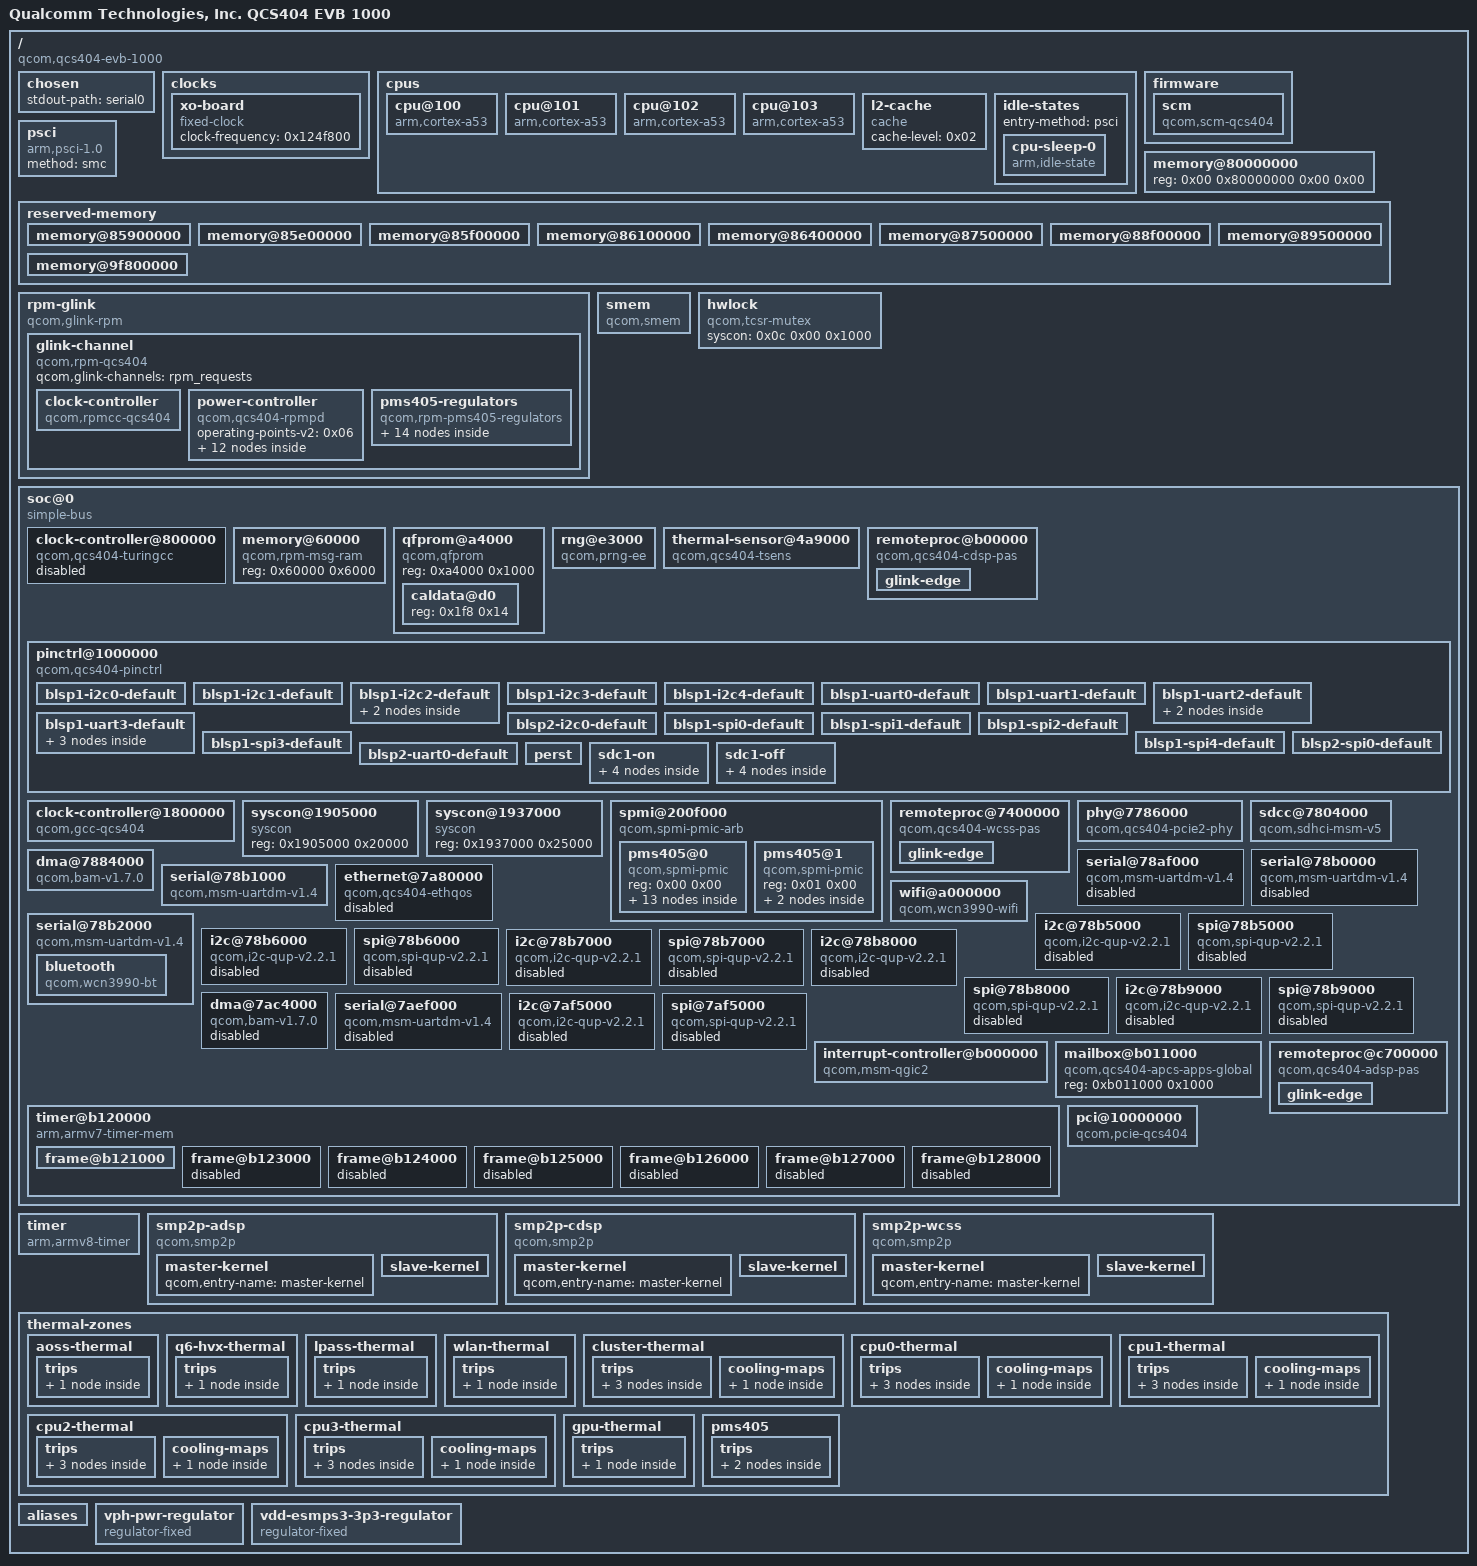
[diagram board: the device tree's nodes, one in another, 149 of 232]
/dts-v1/;

/ {
	interrupt-parent = <0x01>;
	#address-cells = <0x02>;
	#size-cells = <0x02>;
	model = "Qualcomm Technologies, Inc. QCS404 EVB 1000";
	compatible = "qcom,qcs404-evb-1000\0qcom,qcs404-evb\0qcom,qcs404";

	chosen {
		stdout-path = "serial0";
	};

	clocks {

		xo-board {
			compatible = "fixed-clock";
			#clock-cells = <0x00>;
			clock-frequency = <0x124f800>;
			phandle = <0x10>;
		};
	};

	cpus {
		#address-cells = <0x01>;
		#size-cells = <0x00>;

		cpu@100 {
			device_type = "cpu";
			compatible = "arm,cortex-a53";
			reg = <0x100>;
			enable-method = "psci";
			cpu-idle-states = <0x02>;
			next-level-cache = <0x03>;
			#cooling-cells = <0x02>;
			phandle = <0x3d>;
		};

		cpu@101 {
			device_type = "cpu";
			compatible = "arm,cortex-a53";
			reg = <0x101>;
			enable-method = "psci";
			cpu-idle-states = <0x02>;
			next-level-cache = <0x03>;
			#cooling-cells = <0x02>;
			phandle = <0x3e>;
		};

		cpu@102 {
			device_type = "cpu";
			compatible = "arm,cortex-a53";
			reg = <0x102>;
			enable-method = "psci";
			cpu-idle-states = <0x02>;
			next-level-cache = <0x03>;
			#cooling-cells = <0x02>;
			phandle = <0x3f>;
		};

		cpu@103 {
			device_type = "cpu";
			compatible = "arm,cortex-a53";
			reg = <0x103>;
			enable-method = "psci";
			cpu-idle-states = <0x02>;
			next-level-cache = <0x03>;
			#cooling-cells = <0x02>;
			phandle = <0x40>;
		};

		l2-cache {
			compatible = "cache";
			cache-level = <0x02>;
			phandle = <0x03>;
		};

		idle-states {
			entry-method = "psci";

			cpu-sleep-0 {
				compatible = "arm,idle-state";
				idle-state-name = "standalone-power-collapse";
				arm,psci-suspend-param = <0x40000003>;
				entry-latency-us = <0x7d>;
				exit-latency-us = <0xb4>;
				min-residency-us = <0x253>;
				local-timer-stop;
				phandle = <0x02>;
			};
		};
	};

	firmware {

		scm {
			compatible = "qcom,scm-qcs404\0qcom,scm";
			#reset-cells = <0x01>;
			phandle = <0x46>;
		};
	};

	memory@80000000 {
		device_type = "memory";
		reg = <0x00 0x80000000 0x00 0x00>;
	};

	psci {
		compatible = "arm,psci-1.0";
		method = "smc";
	};

	reserved-memory {
		#address-cells = <0x02>;
		#size-cells = <0x02>;
		ranges;

		memory@85900000 {
			reg = <0x00 0x85900000 0x00 0x500000>;
			no-map;
			phandle = <0x47>;
		};

		memory@85e00000 {
			reg = <0x00 0x85e00000 0x00 0x100000>;
			no-map;
			phandle = <0x48>;
		};

		memory@85f00000 {
			reg = <0x00 0x85f00000 0x00 0x200000>;
			no-map;
			phandle = <0x0a>;
		};

		memory@86100000 {
			reg = <0x00 0x86100000 0x00 0x300000>;
			no-map;
			phandle = <0x49>;
		};

		memory@86400000 {
			reg = <0x00 0x86400000 0x00 0x1100000>;
			no-map;
			phandle = <0x18>;
		};

		memory@87500000 {
			reg = <0x00 0x87500000 0x00 0x1a00000>;
			no-map;
			phandle = <0x37>;
		};

		memory@88f00000 {
			reg = <0x00 0x88f00000 0x00 0x600000>;
			no-map;
			phandle = <0x13>;
		};

		memory@89500000 {
			reg = <0x00 0x89500000 0x00 0x100000>;
			no-map;
			phandle = <0x22>;
		};

		memory@9f800000 {
			reg = <0x00 0x9f800000 0x00 0x800000>;
			no-map;
			phandle = <0x4a>;
		};
	};

	rpm-glink {
		compatible = "qcom,glink-rpm";
		interrupts = <0x00 0xa8 0x01>;
		qcom,rpm-msg-ram = <0x04>;
		mboxes = <0x05 0x00>;

		glink-channel {
			compatible = "qcom,rpm-qcs404";
			qcom,glink-channels = "rpm_requests";
			phandle = <0x4b>;

			clock-controller {
				compatible = "qcom,rpmcc-qcs404";
				#clock-cells = <0x01>;
				phandle = <0x4c>;
			};

			power-controller {
				compatible = "qcom,qcs404-rpmpd";
				#power-domain-cells = <0x01>;
				operating-points-v2 = <0x06>;
				phandle = <0x4d>;

				opp-table {
					compatible = "operating-points-v2";
					phandle = <0x06>;

					opp1 {
						opp-level = <0x10>;
						phandle = <0x4e>;
					};

					opp2 {
						opp-level = <0x20>;
						phandle = <0x4f>;
					};

					opp3 {
						opp-level = <0x30>;
						phandle = <0x50>;
					};

					opp4 {
						opp-level = <0x40>;
						phandle = <0x51>;
					};

					opp5 {
						opp-level = <0x80>;
						phandle = <0x52>;
					};

					opp6 {
						opp-level = <0xc0>;
						phandle = <0x53>;
					};

					opp7 {
						opp-level = <0x100>;
						phandle = <0x54>;
					};

					opp8 {
						opp-level = <0x140>;
						phandle = <0x55>;
					};

					opp9 {
						opp-level = <0x180>;
						phandle = <0x56>;
					};

					opp10 {
						opp-level = <0x1a0>;
						phandle = <0x57>;
					};

					opp11 {
						opp-level = <0x200>;
						phandle = <0x58>;
					};
				};
			};

			pms405-regulators {
				compatible = "qcom,rpm-pms405-regulators";
				vdd_s1-supply = <0x07>;
				vdd_s2-supply = <0x07>;
				vdd_s3-supply = <0x07>;
				vdd_s4-supply = <0x07>;
				vdd_s5-supply = <0x07>;
				vdd_l1_l2-supply = <0x08>;
				vdd_l3_l8-supply = <0x08>;
				vdd_l4-supply = <0x08>;
				vdd_l5_l6-supply = <0x09>;
				vdd_l7-supply = <0x07>;
				vdd_l9-supply = <0x08>;
				vdd_l10_l11_l12_l13-supply = <0x07>;

				s4 {
					regulator-min-microvolt = <0x1a5e00>;
					regulator-max-microvolt = <0x1d4c00>;
					phandle = <0x09>;
				};

				s5 {
					regulator-min-microvolt = <0x14a140>;
					regulator-max-microvolt = <0x14a140>;
					phandle = <0x08>;
				};

				l1 {
					regulator-min-microvolt = <0x12ebc0>;
					regulator-max-microvolt = <0x14a140>;
					phandle = <0x24>;
				};

				l2 {
					regulator-min-microvolt = <0xffdc0>;
					regulator-max-microvolt = <0x138800>;
					phandle = <0x23>;
				};

				l3 {
					regulator-min-microvolt = <0xffdc0>;
					regulator-max-microvolt = <0x11b340>;
					phandle = <0x1a>;
				};

				l4 {
					regulator-min-microvolt = <0x1174c0>;
					regulator-max-microvolt = <0x132a40>;
					phandle = <0x59>;
				};

				l5 {
					regulator-min-microvolt = <0x1b7740>;
					regulator-max-microvolt = <0x1b7740>;
					phandle = <0x1b>;
				};

				l6 {
					regulator-min-microvolt = <0x1b7740>;
					regulator-max-microvolt = <0x1b7740>;
					regulator-always-on;
					phandle = <0x26>;
				};

				l7 {
					regulator-min-microvolt = <0x18a880>;
					regulator-max-microvolt = <0x2dc6c0>;
					phandle = <0x5a>;
				};

				l8 {
					regulator-min-microvolt = <0x115580>;
					regulator-max-microvolt = <0x14a140>;
					phandle = <0x5b>;
				};

				l10 {
					regulator-min-microvolt = <0x2cccc0>;
					regulator-max-microvolt = <0x2f1e80>;
					phandle = <0x5c>;
				};

				l11 {
					regulator-min-microvolt = <0x292340>;
					regulator-max-microvolt = <0x326a40>;
					phandle = <0x5d>;
				};

				l12 {
					regulator-min-microvolt = <0x2d49c0>;
					regulator-max-microvolt = <0x325aa0>;
					phandle = <0x5e>;
				};

				l13 {
					regulator-min-microvolt = <0x2dc6c0>;
					regulator-max-microvolt = <0x325aa0>;
					phandle = <0x5f>;
				};
			};
		};
	};

	smem {
		compatible = "qcom,smem";
		memory-region = <0x0a>;
		qcom,rpm-msg-ram = <0x04>;
		hwlocks = <0x0b 0x03>;
	};

	hwlock {
		compatible = "qcom,tcsr-mutex";
		syscon = <0x0c 0x00 0x1000>;
		#hwlock-cells = <0x01>;
		phandle = <0x0b>;
	};

	soc@0 {
		#address-cells = <0x01>;
		#size-cells = <0x01>;
		ranges = <0x00 0x00 0x00 0xffffffff>;
		compatible = "simple-bus";
		phandle = <0x60>;

		clock-controller@800000 {
			compatible = "qcom,qcs404-turingcc";
			reg = <0x800000 0x30000>;
			clocks = <0x0d 0x8f>;
			#clock-cells = <0x01>;
			#reset-cells = <0x01>;
			status = "disabled";
			phandle = <0x11>;
		};

		memory@60000 {
			compatible = "qcom,rpm-msg-ram";
			reg = <0x60000 0x6000>;
			phandle = <0x04>;
		};

		qfprom@a4000 {
			compatible = "qcom,qfprom";
			reg = <0xa4000 0x1000>;
			#address-cells = <0x01>;
			#size-cells = <0x01>;
			phandle = <0x61>;

			caldata@d0 {
				reg = <0x1f8 0x14>;
				phandle = <0x0e>;
			};
		};

		rng@e3000 {
			compatible = "qcom,prng-ee";
			reg = <0xe3000 0x1000>;
			clocks = <0x0d 0x4e>;
			clock-names = "core";
			phandle = <0x62>;
		};

		thermal-sensor@4a9000 {
			compatible = "qcom,qcs404-tsens\0qcom,tsens-v1";
			reg = <0x4a9000 0x1000 0x4a8000 0x1000>;
			nvmem-cells = <0x0e>;
			nvmem-cell-names = "calib";
			#qcom,sensors = <0x0a>;
			#thermal-sensor-cells = <0x01>;
			phandle = <0x3b>;
		};

		remoteproc@b00000 {
			compatible = "qcom,qcs404-cdsp-pas";
			reg = <0xb00000 0x4040>;
			interrupts-extended = <0x01 0x00 0xe5 0x01 0x0f 0x00 0x01 0x0f 0x01 0x01 0x0f 0x02 0x01 0x0f 0x03 0x01>;
			interrupt-names = "wdog\0fatal\0ready\0handover\0stop-ack";
			clocks = <0x10 0x0d 0x8f 0x0d 0x91 0x0d 0x90 0x11 0x02 0x11 0x03 0x11 0x01 0x11 0x00>;
			clock-names = "xo\0sway\0tbu\0bimc\0ahb_aon\0q6ss_slave\0q6ss_master\0q6_axim";
			resets = <0x0d 0x0e>;
			reset-names = "restart";
			qcom,halt-regs = <0x12 0x19004>;
			memory-region = <0x13>;
			qcom,smem-states = <0x14 0x00>;
			qcom,smem-state-names = "stop";
			status = "ok";
			phandle = <0x63>;

			glink-edge {
				interrupts = <0x00 0x8d 0x01>;
				qcom,remote-pid = <0x05>;
				mboxes = <0x05 0x0c>;
				label = "cdsp";
			};
		};

		pinctrl@1000000 {
			compatible = "qcom,qcs404-pinctrl";
			reg = <0x1000000 0x200000 0x1300000 0x200000 0x7b00000 0x200000>;
			reg-names = "south\0north\0east";
			interrupts = <0x00 0xd0 0x04>;
			gpio-ranges = <0x15 0x00 0x00 0x78>;
			gpio-controller;
			#gpio-cells = <0x02>;
			interrupt-controller;
			#interrupt-cells = <0x02>;
			phandle = <0x15>;

			blsp1-i2c0-default {
				pins = "gpio32\0gpio33";
				function = "blsp_i2c0";
				phandle = <0x28>;
			};

			blsp1-i2c1-default {
				pins = "gpio24\0gpio25";
				function = "blsp_i2c1";
				phandle = <0x2a>;
			};

			blsp1-i2c2-default {
				phandle = <0x2c>;

				sda {
					pins = "gpio19";
					function = "blsp_i2c_sda_a2";
				};

				scl {
					pins = "gpio20";
					function = "blsp_i2c_scl_a2";
				};
			};

			blsp1-i2c3-default {
				pins = "gpio84\0gpio85";
				function = "blsp_i2c3";
				phandle = <0x2e>;
			};

			blsp1-i2c4-default {
				pins = "gpio117\0gpio118";
				function = "blsp_i2c4";
				phandle = <0x30>;
			};

			blsp1-uart0-default {
				pins = "gpio30\0gpio31\0gpio32\0gpio33";
				function = "blsp_uart0";
				phandle = <0x1f>;
			};

			blsp1-uart1-default {
				pins = "gpio22\0gpio23";
				function = "blsp_uart1";
				phandle = <0x20>;
			};

			blsp1-uart2-default {
				phandle = <0x21>;

				rx {
					pins = "gpio18";
					function = "blsp_uart_rx_a2";
					drive-strength = <0x02>;
					bias-disable;
				};

				tx {
					pins = "gpio17";
					function = "blsp_uart_tx_a2";
					drive-strength = <0x02>;
					bias-disable;
				};
			};

			blsp1-uart3-default {
				pins = "gpio82\0gpio83\0gpio84\0gpio85";
				function = "blsp_uart3";
				phandle = <0x25>;

				cts {
					pins = "gpio84";
					bias-disable;
				};

				rts-tx {
					pins = "gpio85\0gpio82";
					drive-strength = <0x02>;
					bias-disable;
				};

				rx {
					pins = "gpio83";
					bias-pull-up;
				};
			};

			blsp2-i2c0-default {
				pins = "gpio28\0gpio29";
				function = "blsp_i2c5";
				phandle = <0x34>;
			};

			blsp1-spi0-default {
				pins = "gpio30\0gpio31\0gpio32\0gpio33";
				function = "blsp_spi0";
				phandle = <0x29>;
			};

			blsp1-spi1-default {
				pins = "gpio22\0gpio23\0gpio24\0gpio25";
				function = "blsp_spi1";
				phandle = <0x2b>;
			};

			blsp1-spi2-default {
				pins = "gpio17\0gpio18\0gpio19\0gpio20";
				function = "blsp_spi2";
				phandle = <0x2d>;
			};

			blsp1-spi3-default {
				pins = "gpio82\0gpio83\0gpio84\0gpio85";
				function = "blsp_spi3";
				phandle = <0x2f>;
			};

			blsp1-spi4-default {
				pins = "gpio37\0gpio38\0gpio117\0gpio118";
				function = "blsp_spi4";
				phandle = <0x31>;
			};

			blsp2-spi0-default {
				pins = "gpio26\0gpio27\0gpio28\0gpio29";
				function = "blsp_spi5";
				phandle = <0x35>;
			};

			blsp2-uart0-default {
				pins = "gpio26\0gpio27\0gpio28\0gpio29";
				function = "blsp_uart5";
				phandle = <0x33>;
			};

			perst {
				pins = "gpio43";
				function = "gpio";
				drive-strength = <0x02>;
				bias-disable;
				output-low;
				phandle = <0x3a>;
			};

			sdc1-on {
				phandle = <0x1c>;

				clk {
					pins = "sdc1_clk";
					bias-disable;
					drive-strength = <0x10>;
				};

				cmd {
					pins = "sdc1_cmd";
					bias-pull-up;
					drive-strength = <0x0a>;
				};

				data {
					pins = "sdc1_data";
					bias-pull-up;
					drive-strength = <0x0a>;
				};

				rclk {
					pins = "sdc1_rclk";
					bias-pull-down;
				};
			};

			sdc1-off {
				phandle = <0x1d>;

				clk {
					pins = "sdc1_clk";
					bias-disable;
					drive-strength = <0x02>;
				};

				cmd {
					pins = "sdc1_cmd";
					bias-pull-up;
					drive-strength = <0x02>;
				};

				data {
					pins = "sdc1_data";
					bias-pull-up;
					drive-strength = <0x02>;
				};

				rclk {
					pins = "sdc1_rclk";
					bias-pull-down;
				};
			};
		};

		clock-controller@1800000 {
			compatible = "qcom,gcc-qcs404";
			reg = <0x1800000 0x80000>;
			#clock-cells = <0x01>;
			#reset-cells = <0x01>;
			assigned-clocks = <0x0d 0x00>;
			assigned-clock-rates = <0x124f800>;
			protected-clocks = <0x90 0x8f 0x92 0x91 0x8d 0x8e>;
			phandle = <0x0d>;
		};

		syscon@1905000 {
			compatible = "syscon";
			reg = <0x1905000 0x20000>;
			phandle = <0x0c>;
		};

		syscon@1937000 {
			compatible = "syscon";
			reg = <0x1937000 0x25000>;
			phandle = <0x12>;
		};

		spmi@200f000 {
			compatible = "qcom,spmi-pmic-arb";
			reg = <0x200f000 0x1000 0x2400000 0x800000 0x2c00000 0x800000 0x3800000 0x200000 0x200a000 0x2100>;
			reg-names = "core\0chnls\0obsrvr\0intr\0cnfg";
			interrupt-names = "periph_irq";
			interrupts = <0x00 0xbe 0x04>;
			qcom,ee = <0x00>;
			qcom,channel = <0x00>;
			#address-cells = <0x02>;
			#size-cells = <0x00>;
			interrupt-controller;
			#interrupt-cells = <0x04>;
			phandle = <0x64>;

			pms405@0 {
				compatible = "qcom,spmi-pmic";
				reg = <0x00 0x00>;
				#address-cells = <0x01>;
				#size-cells = <0x00>;
				phandle = <0x65>;

				gpio@c000 {
					compatible = "qcom,pms405-gpio";
					reg = <0xc000>;
					gpio-controller;
					#gpio-cells = <0x02>;
					interrupts = <0x00 0xc0 0x00 0x00 0x00 0xc1 0x00 0x00 0x00 0xc2 0x00 0x00 0x00 0xc3 0x00 0x00 0x00 0xc4 0x00 0x00 0x00 0xc5 0x00 0x00 0x00 0xc6 0x00 0x00 0x00 0xc7 0x00 0x00 0x00 0xc8 0x00 0x00 0x00 0xc9 0x00 0x00 0x00 0xca 0x00 0x00 0x00 0xcb 0x00 0x00>;
					phandle = <0x66>;
				};

				pon@800 {
					compatible = "qcom,pms405-pon";
					reg = <0x800>;
					mode-bootloader = <0x02>;
					mode-recovery = <0x01>;

					pwrkey {
						compatible = "qcom,pm8941-pwrkey";
						interrupts = <0x00 0x08 0x00 0x03>;
						debounce = <0x3d09>;
						bias-pull-up;
						linux,code = <0x74>;
					};
				};

				temp-alarm@2400 {
					compatible = "qcom,spmi-temp-alarm";
					reg = <0x2400>;
					interrupts = <0x00 0x24 0x00 0x01>;
					io-channels = <0x16 0x06>;
					io-channel-names = "thermal";
					#thermal-sensor-cells = <0x00>;
					phandle = <0x45>;
				};

				adc@3100 {
					compatible = "qcom,pms405-adc\0qcom,spmi-adc-rev2";
					reg = <0x3100>;
					interrupts = <0x00 0x31 0x00 0x01>;
					#address-cells = <0x01>;
					#size-cells = <0x00>;
					#io-channel-cells = <0x01>;
					phandle = <0x16>;

					ref_gnd@0 {
						reg = <0x00>;
						qcom,pre-scaling = <0x01 0x01>;
					};

					vref_1p25@1 {
						reg = <0x01>;
						qcom,pre-scaling = <0x01 0x01>;
					};

					vph_pwr@131 {
						reg = <0x83>;
						qcom,pre-scaling = <0x01 0x03>;
						phandle = <0x67>;
					};

					die_temp@6 {
						reg = <0x06>;
						qcom,pre-scaling = <0x01 0x01>;
					};

					thermistor1@77 {
						reg = <0x4d>;
						qcom,ratiometric;
						qcom,hw-settle-time = <0xc8>;
						qcom,pre-scaling = <0x01 0x01>;
						phandle = <0x68>;
					};

					thermistor3@79 {
						reg = <0x4f>;
						qcom,ratiometric;
						qcom,hw-settle-time = <0xc8>;
						qcom,pre-scaling = <0x01 0x01>;
						phandle = <0x69>;
					};

					xo_temp@76 {
						reg = <0x4c>;
						qcom,ratiometric;
						qcom,hw-settle-time = <0xc8>;
						qcom,pre-scaling = <0x01 0x01>;
						phandle = <0x6a>;
					};
				};

				rtc@6000 {
					compatible = "qcom,pm8941-rtc";
					reg = <0x6000>;
					reg-names = "rtc\0alarm";
					interrupts = <0x00 0x61 0x01 0x00>;
				};
			};

			pms405@1 {
				compatible = "qcom,spmi-pmic";
				reg = <0x01 0x00>;
				phandle = <0x6b>;

				regulators {
					compatible = "qcom,pms405-regulators";
					vdd_s3-supply = <0x07>;
					phandle = <0x6c>;

					s3 {
						regulator-always-on;
						regulator-boot-on;
						regulator-name = "vdd_apc";
						regulator-initial-mode = <0x01>;
						regulator-min-microvolt = <0xffdc0>;
						regulator-max-microvolt = <0x151e40>;
						phandle = <0x6d>;
					};
				};
			};
		};

		remoteproc@7400000 {
			compatible = "qcom,qcs404-wcss-pas";
			reg = <0x7400000 0x4040>;
			interrupts-extended = <0x01 0x00 0x99 0x01 0x17 0x00 0x01 0x17 0x01 0x01 0x17 0x02 0x01 0x17 0x03 0x01>;
			interrupt-names = "wdog\0fatal\0ready\0handover\0stop-ack";
			clocks = <0x10>;
			clock-names = "xo";
			memory-region = <0x18>;
			qcom,smem-states = <0x19 0x00>;
			qcom,smem-state-names = "stop";
			status = "ok";
			phandle = <0x6e>;

			glink-edge {
				interrupts = <0x00 0x9c 0x01>;
				qcom,remote-pid = <0x01>;
				mboxes = <0x05 0x10>;
				label = "wcss";
			};
		};

		phy@7786000 {
			compatible = "qcom,qcs404-pcie2-phy\0qcom,pcie2-phy";
			reg = <0x7786000 0xb8>;
			clocks = <0x0d 0x47>;
			resets = <0x0d 0x0c 0x0d 0x15>;
			reset-names = "phy\0pipe";
			clock-output-names = "pcie_0_pipe_clk";
			#phy-cells = <0x00>;
			status = "ok";
			vdda-vp-supply = <0x1a>;
			vdda-vph-supply = <0x1b>;
			phandle = <0x39>;
		};

		sdcc@7804000 {
			compatible = "qcom,sdhci-msm-v5";
			reg = <0x7804000 0x1000 0x7805000 0x1000>;
			reg-names = "hc_mem\0cmdq_mem";
			interrupts = <0x00 0x7b 0x04 0x00 0x8a 0x04>;
			interrupt-names = "hc_irq\0pwr_irq";
			clocks = <0x0d 0x53 0x0d 0x52 0x10>;
			clock-names = "core\0iface\0xo";
			status = "ok";
			mmc-ddr-1_8v;
			mmc-hs400-1_8v;
			bus-width = <0x08>;
			non-removable;
			pinctrl-names = "default\0sleep";
			pinctrl-0 = <0x1c>;
			pinctrl-1 = <0x1d>;
			phandle = <0x6f>;
		};

		dma@7884000 {
			compatible = "qcom,bam-v1.7.0";
			reg = <0x7884000 0x25000>;
			interrupts = <0x00 0xee 0x04>;
			clocks = <0x0d 0x1b>;
			clock-names = "bam_clk";
			#dma-cells = <0x01>;
			qcom,ee = <0x00>;
			status = "okay";
			qcom,controlled-remotely;
			phandle = <0x1e>;
		};

		serial@78af000 {
			compatible = "qcom,msm-uartdm-v1.4\0qcom,msm-uartdm";
			reg = <0x78af000 0x200>;
			interrupts = <0x00 0x6b 0x04>;
			clocks = <0x0d 0x26 0x0d 0x1b>;
			clock-names = "core\0iface";
			dmas = <0x1e 0x01 0x1e 0x00>;
			dma-names = "rx\0tx";
			pinctrl-names = "default";
			pinctrl-0 = <0x1f>;
			status = "disabled";
			phandle = <0x70>;
		};

		serial@78b0000 {
			compatible = "qcom,msm-uartdm-v1.4\0qcom,msm-uartdm";
			reg = <0x78b0000 0x200>;
			interrupts = <0x00 0x6c 0x04>;
			clocks = <0x0d 0x27 0x0d 0x1b>;
			clock-names = "core\0iface";
			dmas = <0x1e 0x03 0x1e 0x02>;
			dma-names = "rx\0tx";
			pinctrl-names = "default";
			pinctrl-0 = <0x20>;
			status = "disabled";
			phandle = <0x71>;
		};

		serial@78b1000 {
			compatible = "qcom,msm-uartdm-v1.4\0qcom,msm-uartdm";
			reg = <0x78b1000 0x200>;
			interrupts = <0x00 0x76 0x04>;
			clocks = <0x0d 0x28 0x0d 0x1b>;
			clock-names = "core\0iface";
			dmas = <0x1e 0x05 0x1e 0x04>;
			dma-names = "rx\0tx";
			pinctrl-names = "default";
			pinctrl-0 = <0x21>;
			status = "okay";
			phandle = <0x72>;
		};

		ethernet@7a80000 {
			compatible = "qcom,qcs404-ethqos";
			reg = <0x7a80000 0x10000 0x7a96000 0x100>;
			reg-names = "stmmaceth\0rgmii";
			clock-names = "stmmaceth\0pclk\0ptp_ref\0rgmii";
			clocks = <0x0d 0x31 0x0d 0x34 0x0d 0x32 0x0d 0x33>;
			interrupts = <0x00 0x38 0x04 0x00 0x37 0x04>;
			interrupt-names = "macirq\0eth_lpi";
			snps,tso;
			rx-fifo-depth = <0x1000>;
			tx-fifo-depth = <0x1000>;
			status = "disabled";
			phandle = <0x73>;
		};

		wifi@a000000 {
			compatible = "qcom,wcn3990-wifi";
			reg = <0xa000000 0x800000>;
			reg-names = "membase";
			memory-region = <0x22>;
			interrupts = <0x00 0x115 0x04 0x00 0x116 0x04 0x00 0x117 0x04 0x00 0x118 0x04 0x00 0x119 0x04 0x00 0x11a 0x04 0x00 0x11b 0x04 0x00 0x11c 0x04 0x00 0x11d 0x04 0x00 0x11e 0x04 0x00 0x11f 0x04 0x00 0x120 0x04>;
			status = "okay";
			vdd-0.8-cx-mx-supply = <0x23>;
			vdd-1.8-xo-supply = <0x1b>;
			vdd-1.3-rfa-supply = <0x24>;
			phandle = <0x74>;
		};

		serial@78b2000 {
			compatible = "qcom,msm-uartdm-v1.4\0qcom,msm-uartdm";
			reg = <0x78b2000 0x200>;
			interrupts = <0x00 0x77 0x04>;
			clocks = <0x0d 0x29 0x0d 0x1b>;
			clock-names = "core\0iface";
			dmas = <0x1e 0x07 0x1e 0x06>;
			dma-names = "rx\0tx";
			pinctrl-names = "default";
			pinctrl-0 = <0x25>;
			status = "okay";
			phandle = <0x75>;

			bluetooth {
				compatible = "qcom,wcn3990-bt";
				vddio-supply = <0x26>;
				vddxo-supply = <0x1b>;
				vddrf-supply = <0x24>;
				vddch0-supply = <0x27>;
				local-bd-address = [02 00 00 00 5a ad];
				max-speed = <0x30d400>;
			};
		};

		i2c@78b5000 {
			compatible = "qcom,i2c-qup-v2.2.1";
			reg = <0x78b5000 0x600>;
			interrupts = <0x00 0x5f 0x04>;
			clocks = <0x0d 0x1b 0x0d 0x1c>;
			clock-names = "iface\0core";
			pinctrl-names = "default";
			pinctrl-0 = <0x28>;
			#address-cells = <0x01>;
			#size-cells = <0x00>;
			status = "disabled";
			phandle = <0x76>;
		};

		spi@78b5000 {
			compatible = "qcom,spi-qup-v2.2.1";
			reg = <0x78b5000 0x600>;
			interrupts = <0x00 0x5f 0x04>;
			clocks = <0x0d 0x1b 0x0d 0x1d>;
			clock-names = "iface\0core";
			pinctrl-names = "default";
			pinctrl-0 = <0x29>;
			#address-cells = <0x01>;
			#size-cells = <0x00>;
			status = "disabled";
			phandle = <0x77>;
		};

		i2c@78b6000 {
			compatible = "qcom,i2c-qup-v2.2.1";
			reg = <0x78b6000 0x600>;
			interrupts = <0x00 0x60 0x04>;
			clocks = <0x0d 0x1b 0x0d 0x1e>;
			clock-names = "iface\0core";
			pinctrl-names = "default";
			pinctrl-0 = <0x2a>;
			#address-cells = <0x01>;
			#size-cells = <0x00>;
			status = "disabled";
			phandle = <0x78>;
		};

		spi@78b6000 {
			compatible = "qcom,spi-qup-v2.2.1";
			reg = <0x78b6000 0x600>;
			interrupts = <0x00 0x60 0x04>;
			clocks = <0x0d 0x1b 0x0d 0x1f>;
			clock-names = "iface\0core";
			pinctrl-names = "default";
			pinctrl-0 = <0x2b>;
			#address-cells = <0x01>;
			#size-cells = <0x00>;
			status = "disabled";
			phandle = <0x79>;
		};

		i2c@78b7000 {
			compatible = "qcom,i2c-qup-v2.2.1";
			reg = <0x78b7000 0x600>;
			interrupts = <0x00 0x61 0x04>;
			clocks = <0x0d 0x1b 0x0d 0x20>;
			clock-names = "iface\0core";
			pinctrl-names = "default";
			pinctrl-0 = <0x2c>;
			#address-cells = <0x01>;
			#size-cells = <0x00>;
			status = "disabled";
			phandle = <0x7a>;
		};

		spi@78b7000 {
			compatible = "qcom,spi-qup-v2.2.1";
			reg = <0x78b7000 0x600>;
			interrupts = <0x00 0x61 0x04>;
			clocks = <0x0d 0x1b 0x0d 0x21>;
			clock-names = "iface\0core";
			pinctrl-names = "default";
			pinctrl-0 = <0x2d>;
			#address-cells = <0x01>;
			#size-cells = <0x00>;
			status = "disabled";
			phandle = <0x7b>;
		};

		i2c@78b8000 {
			compatible = "qcom,i2c-qup-v2.2.1";
			reg = <0x78b8000 0x600>;
			interrupts = <0x00 0x62 0x04>;
			clocks = <0x0d 0x1b 0x0d 0x22>;
			clock-names = "iface\0core";
			pinctrl-names = "default";
			pinctrl-0 = <0x2e>;
			#address-cells = <0x01>;
			#size-cells = <0x00>;
			status = "disabled";
			phandle = <0x7c>;
		};

		spi@78b8000 {
			compatible = "qcom,spi-qup-v2.2.1";
			reg = <0x78b8000 0x600>;
			interrupts = <0x00 0x62 0x04>;
			clocks = <0x0d 0x1b 0x0d 0x23>;
			clock-names = "iface\0core";
			pinctrl-names = "default";
			pinctrl-0 = <0x2f>;
			#address-cells = <0x01>;
			#size-cells = <0x00>;
			status = "disabled";
			phandle = <0x7d>;
		};

		i2c@78b9000 {
			compatible = "qcom,i2c-qup-v2.2.1";
			reg = <0x78b9000 0x600>;
			interrupts = <0x00 0x63 0x04>;
			clocks = <0x0d 0x1b 0x0d 0x24>;
			clock-names = "iface\0core";
			pinctrl-names = "default";
			pinctrl-0 = <0x30>;
			#address-cells = <0x01>;
			#size-cells = <0x00>;
			status = "disabled";
			phandle = <0x7e>;
		};

		spi@78b9000 {
			compatible = "qcom,spi-qup-v2.2.1";
			reg = <0x78b9000 0x600>;
			interrupts = <0x00 0x63 0x04>;
			clocks = <0x0d 0x1b 0x0d 0x25>;
			clock-names = "iface\0core";
			pinctrl-names = "default";
			pinctrl-0 = <0x31>;
			#address-cells = <0x01>;
			#size-cells = <0x00>;
			status = "disabled";
			phandle = <0x7f>;
		};

		dma@7ac4000 {
			compatible = "qcom,bam-v1.7.0";
			reg = <0x7ac4000 0x17000>;
			interrupts = <0x00 0xef 0x04>;
			clocks = <0x0d 0x2a>;
			clock-names = "bam_clk";
			#dma-cells = <0x01>;
			qcom,ee = <0x00>;
			status = "disabled";
			qcom,controlled-remotely;
			phandle = <0x32>;
		};

		serial@7aef000 {
			compatible = "qcom,msm-uartdm-v1.4\0qcom,msm-uartdm";
			reg = <0x7aef000 0x200>;
			interrupts = <0x00 0x129 0x04>;
			clocks = <0x0d 0x2d 0x0d 0x2a>;
			clock-names = "core\0iface";
			dmas = <0x32 0x01 0x32 0x00>;
			dma-names = "rx\0tx";
			pinctrl-names = "default";
			pinctrl-0 = <0x33>;
			status = "disabled";
			phandle = <0x80>;
		};

		i2c@7af5000 {
			compatible = "qcom,i2c-qup-v2.2.1";
			reg = <0x7af5000 0x600>;
			interrupts = <0x00 0x12b 0x04>;
			clocks = <0x0d 0x2a 0x0d 0x2b>;
			clock-names = "iface\0core";
			pinctrl-names = "default";
			pinctrl-0 = <0x34>;
			#address-cells = <0x01>;
			#size-cells = <0x00>;
			status = "disabled";
			phandle = <0x81>;
		};

		spi@7af5000 {
			compatible = "qcom,spi-qup-v2.2.1";
			reg = <0x7af5000 0x600>;
			interrupts = <0x00 0x12b 0x04>;
			clocks = <0x0d 0x2a 0x0d 0x2c>;
			clock-names = "iface\0core";
			pinctrl-names = "default";
			pinctrl-0 = <0x35>;
			#address-cells = <0x01>;
			#size-cells = <0x00>;
			status = "disabled";
			phandle = <0x82>;
		};

		interrupt-controller@b000000 {
			compatible = "qcom,msm-qgic2";
			interrupt-controller;
			#interrupt-cells = <0x03>;
			reg = <0xb000000 0x1000 0xb002000 0x1000>;
			phandle = <0x01>;
		};

		mailbox@b011000 {
			compatible = "qcom,qcs404-apcs-apps-global\0syscon";
			reg = <0xb011000 0x1000>;
			#mbox-cells = <0x01>;
			phandle = <0x05>;
		};

		timer@b120000 {
			#address-cells = <0x01>;
			#size-cells = <0x01>;
			ranges;
			compatible = "arm,armv7-timer-mem";
			reg = <0xb120000 0x1000>;
			clock-frequency = <0x124f800>;

			frame@b121000 {
				frame-number = <0x00>;
				interrupts = <0x00 0x08 0x04 0x00 0x07 0x04>;
				reg = <0xb121000 0x1000 0xb122000 0x1000>;
			};

			frame@b123000 {
				frame-number = <0x01>;
				interrupts = <0x00 0x09 0x04>;
				reg = <0xb123000 0x1000>;
				status = "disabled";
			};

			frame@b124000 {
				frame-number = <0x02>;
				interrupts = <0x00 0x0a 0x04>;
				reg = <0xb124000 0x1000>;
				status = "disabled";
			};

			frame@b125000 {
				frame-number = <0x03>;
				interrupts = <0x00 0x0b 0x04>;
				reg = <0xb125000 0x1000>;
				status = "disabled";
			};

			frame@b126000 {
				frame-number = <0x04>;
				interrupts = <0x00 0x0c 0x04>;
				reg = <0xb126000 0x1000>;
				status = "disabled";
			};

			frame@b127000 {
				frame-number = <0x05>;
				interrupts = <0x00 0x0d 0x04>;
				reg = <0xb127000 0x1000>;
				status = "disabled";
			};

			frame@b128000 {
				frame-number = <0x06>;
				interrupts = <0x00 0x0e 0x04>;
				reg = <0xb128000 0x1000>;
				status = "disabled";
			};
		};

		remoteproc@c700000 {
			compatible = "qcom,qcs404-adsp-pas";
			reg = <0xc700000 0x4040>;
			interrupts-extended = <0x01 0x00 0x125 0x01 0x36 0x00 0x01 0x36 0x01 0x01 0x36 0x02 0x01 0x36 0x03 0x01>;
			interrupt-names = "wdog\0fatal\0ready\0handover\0stop-ack";
			clocks = <0x10>;
			clock-names = "xo";
			memory-region = <0x37>;
			qcom,smem-states = <0x38 0x00>;
			qcom,smem-state-names = "stop";
			status = "ok";
			phandle = <0x83>;

			glink-edge {
				interrupts = <0x00 0x121 0x01>;
				qcom,remote-pid = <0x02>;
				mboxes = <0x05 0x08>;
				label = "adsp";
			};
		};

		pci@10000000 {
			compatible = "qcom,pcie-qcs404\0snps,dw-pcie";
			reg = <0x10000000 0xf1d 0x10000f20 0xa8 0x7780000 0x2000 0x10001000 0x2000>;
			reg-names = "dbi\0elbi\0parf\0config";
			device_type = "pci";
			linux,pci-domain = <0x00>;
			bus-range = <0x00 0xff>;
			num-lanes = <0x01>;
			#address-cells = <0x03>;
			#size-cells = <0x02>;
			ranges = <0x81000000 0x00 0x00 0x10003000 0x00 0x10000 0x82000000 0x00 0x10013000 0x10013000 0x00 0x7ed000>;
			interrupts = <0x00 0x10a 0x04>;
			interrupt-names = "msi";
			#interrupt-cells = <0x01>;
			interrupt-map-mask = <0x00 0x00 0x00 0x07>;
			interrupt-map = <0x00 0x00 0x00 0x01 0x01 0x00 0x44 0x04 0x00 0x00 0x00 0x02 0x01 0x00 0xe0 0x04 0x00 0x00 0x00 0x03 0x01 0x00 0x10b 0x04 0x00 0x00 0x00 0x04 0x01 0x00 0x10c 0x04>;
			clocks = <0x0d 0x45 0x0d 0x44 0x0d 0x46 0x0d 0x48>;
			clock-names = "iface\0aux\0master_bus\0slave_bus";
			resets = <0x0d 0x12 0x0d 0x11 0x0d 0x0f 0x0d 0x13 0x0d 0x09 0x0d 0x10>;
			reset-names = "axi_m\0axi_s\0axi_m_sticky\0pipe_sticky\0pwr\0ahb";
			phys = <0x39>;
			phy-names = "pciephy";
			status = "ok";
			perst-gpio = <0x15 0x2b 0x01>;
			pinctrl-names = "default";
			pinctrl-0 = <0x3a>;
			phandle = <0x84>;
		};
	};

	timer {
		compatible = "arm,armv8-timer";
		interrupts = <0x01 0x02 0xff08 0x01 0x03 0xff08 0x01 0x04 0xff08 0x01 0x01 0xff08>;
	};

	smp2p-adsp {
		compatible = "qcom,smp2p";
		qcom,smem = <0x1bb 0x1ad>;
		interrupts = <0x00 0x123 0x01>;
		mboxes = <0x05 0x0a>;
		qcom,local-pid = <0x00>;
		qcom,remote-pid = <0x02>;

		master-kernel {
			qcom,entry-name = "master-kernel";
			#qcom,smem-state-cells = <0x01>;
			phandle = <0x38>;
		};

		slave-kernel {
			qcom,entry-name = "slave-kernel";
			interrupt-controller;
			#interrupt-cells = <0x02>;
			phandle = <0x36>;
		};
	};

	smp2p-cdsp {
		compatible = "qcom,smp2p";
		qcom,smem = <0x5e 0x1b0>;
		interrupts = <0x00 0x8f 0x01>;
		mboxes = <0x05 0x0e>;
		qcom,local-pid = <0x00>;
		qcom,remote-pid = <0x05>;

		master-kernel {
			qcom,entry-name = "master-kernel";
			#qcom,smem-state-cells = <0x01>;
			phandle = <0x14>;
		};

		slave-kernel {
			qcom,entry-name = "slave-kernel";
			interrupt-controller;
			#interrupt-cells = <0x02>;
			phandle = <0x0f>;
		};
	};

	smp2p-wcss {
		compatible = "qcom,smp2p";
		qcom,smem = <0x1b3 0x1ac>;
		interrupts = <0x00 0x9e 0x01>;
		mboxes = <0x05 0x12>;
		qcom,local-pid = <0x00>;
		qcom,remote-pid = <0x01>;

		master-kernel {
			qcom,entry-name = "master-kernel";
			#qcom,smem-state-cells = <0x01>;
			phandle = <0x19>;
		};

		slave-kernel {
			qcom,entry-name = "slave-kernel";
			interrupt-controller;
			#interrupt-cells = <0x02>;
			phandle = <0x17>;
		};
	};

	thermal-zones {

		aoss-thermal {
			polling-delay-passive = <0xfa>;
			polling-delay = <0x3e8>;
			thermal-sensors = <0x3b 0x00>;

			trips {

				trip-point0 {
					temperature = <0x19a28>;
					hysteresis = <0x7d0>;
					type = "hot";
					phandle = <0x85>;
				};
			};
		};

		q6-hvx-thermal {
			polling-delay-passive = <0xfa>;
			polling-delay = <0x3e8>;
			thermal-sensors = <0x3b 0x01>;

			trips {

				trip-point0 {
					temperature = <0x19a28>;
					hysteresis = <0x7d0>;
					type = "hot";
					phandle = <0x86>;
				};
			};
		};

		lpass-thermal {
			polling-delay-passive = <0xfa>;
			polling-delay = <0x3e8>;
			thermal-sensors = <0x3b 0x02>;

			trips {

				trip-point0 {
					temperature = <0x19a28>;
					hysteresis = <0x7d0>;
					type = "hot";
					phandle = <0x87>;
				};
			};
		};

		wlan-thermal {
			polling-delay-passive = <0xfa>;
			polling-delay = <0x3e8>;
			thermal-sensors = <0x3b 0x03>;

			trips {

				trip-point0 {
					temperature = <0x19a28>;
					hysteresis = <0x7d0>;
					type = "hot";
					phandle = <0x88>;
				};
			};
		};

		cluster-thermal {
			polling-delay-passive = <0xfa>;
			polling-delay = <0x3e8>;
			thermal-sensors = <0x3b 0x04>;

			trips {

				trip-point0 {
					temperature = <0x17318>;
					hysteresis = <0x7d0>;
					type = "hot";
					phandle = <0x89>;
				};

				trip-point1 {
					temperature = <0x19a28>;
					hysteresis = <0x7d0>;
					type = "passive";
					phandle = <0x3c>;
				};

				cluster_crit {
					temperature = <0x1d4c0>;
					hysteresis = <0x7d0>;
					type = "critical";
					phandle = <0x8a>;
				};
			};

			cooling-maps {

				map0 {
					trip = <0x3c>;
					cooling-device = <0x3d 0xffffffff 0xffffffff 0x3e 0xffffffff 0xffffffff 0x3f 0xffffffff 0xffffffff 0x40 0xffffffff 0xffffffff>;
				};
			};
		};

		cpu0-thermal {
			polling-delay-passive = <0xfa>;
			polling-delay = <0x3e8>;
			thermal-sensors = <0x3b 0x05>;

			trips {

				trip-point0 {
					temperature = <0x17318>;
					hysteresis = <0x7d0>;
					type = "hot";
					phandle = <0x8b>;
				};

				trip-point1 {
					temperature = <0x19a28>;
					hysteresis = <0x7d0>;
					type = "passive";
					phandle = <0x41>;
				};

				cpu_crit {
					temperature = <0x1d4c0>;
					hysteresis = <0x7d0>;
					type = "critical";
					phandle = <0x8c>;
				};
			};

			cooling-maps {

				map0 {
					trip = <0x41>;
					cooling-device = <0x3d 0xffffffff 0xffffffff 0x3e 0xffffffff 0xffffffff 0x3f 0xffffffff 0xffffffff 0x40 0xffffffff 0xffffffff>;
				};
			};
		};

		cpu1-thermal {
			polling-delay-passive = <0xfa>;
			polling-delay = <0x3e8>;
			thermal-sensors = <0x3b 0x06>;

			trips {

				trip-point0 {
					temperature = <0x17318>;
					hysteresis = <0x7d0>;
					type = "hot";
					phandle = <0x8d>;
				};

				trip-point1 {
					temperature = <0x19a28>;
					hysteresis = <0x7d0>;
					type = "passive";
					phandle = <0x42>;
				};

				cpu_crit {
					temperature = <0x1d4c0>;
					hysteresis = <0x7d0>;
					type = "critical";
					phandle = <0x8e>;
				};
			};

			cooling-maps {

				map0 {
					trip = <0x42>;
					cooling-device = <0x3d 0xffffffff 0xffffffff 0x3e 0xffffffff 0xffffffff 0x3f 0xffffffff 0xffffffff 0x40 0xffffffff 0xffffffff>;
				};
			};
		};

		cpu2-thermal {
			polling-delay-passive = <0xfa>;
			polling-delay = <0x3e8>;
			thermal-sensors = <0x3b 0x07>;

			trips {

				trip-point0 {
					temperature = <0x17318>;
					hysteresis = <0x7d0>;
					type = "hot";
					phandle = <0x8f>;
				};

				trip-point1 {
					temperature = <0x19a28>;
					hysteresis = <0x7d0>;
					type = "passive";
					phandle = <0x43>;
				};

				cpu_crit {
					temperature = <0x1d4c0>;
					hysteresis = <0x7d0>;
					type = "critical";
					phandle = <0x90>;
				};
			};

			cooling-maps {

				map0 {
					trip = <0x43>;
					cooling-device = <0x3d 0xffffffff 0xffffffff 0x3e 0xffffffff 0xffffffff 0x3f 0xffffffff 0xffffffff 0x40 0xffffffff 0xffffffff>;
				};
			};
		};

		cpu3-thermal {
			polling-delay-passive = <0xfa>;
			polling-delay = <0x3e8>;
			thermal-sensors = <0x3b 0x08>;

			trips {

				trip-point0 {
					temperature = <0x17318>;
					hysteresis = <0x7d0>;
					type = "hot";
					phandle = <0x91>;
				};

				trip-point1 {
					temperature = <0x19a28>;
					hysteresis = <0x7d0>;
					type = "passive";
					phandle = <0x44>;
				};

				cpu_crit {
					temperature = <0x1d4c0>;
					hysteresis = <0x7d0>;
					type = "critical";
					phandle = <0x92>;
				};
			};

			cooling-maps {

				map0 {
					trip = <0x44>;
					cooling-device = <0x3d 0xffffffff 0xffffffff 0x3e 0xffffffff 0xffffffff 0x3f 0xffffffff 0xffffffff 0x40 0xffffffff 0xffffffff>;
				};
			};
		};

		gpu-thermal {
			polling-delay-passive = <0xfa>;
			polling-delay = <0x3e8>;
			thermal-sensors = <0x3b 0x09>;

			trips {

				trip-point0 {
					temperature = <0x17318>;
					hysteresis = <0x7d0>;
					type = "hot";
					phandle = <0x93>;
				};
			};
		};

		pms405 {
			polling-delay-passive = <0xfa>;
			polling-delay = <0x3e8>;
			thermal-sensors = <0x45>;

			trips {

				pms405-alert0 {
					temperature = <0x19a28>;
					hysteresis = <0x7d0>;
					type = "passive";
					phandle = <0x94>;
				};

				pms405-crit {
					temperature = <0x1e848>;
					hysteresis = <0x7d0>;
					type = "critical";
					phandle = <0x95>;
				};
			};
		};
	};

	aliases {
		serial0 = "/soc@0/serial@78b1000";
		serial1 = "/soc@0/serial@78b2000";
	};

	vph-pwr-regulator {
		compatible = "regulator-fixed";
		regulator-name = "vph_pwr";
		regulator-always-on;
		regulator-boot-on;
		phandle = <0x07>;
	};

	vdd-esmps3-3p3-regulator {
		compatible = "regulator-fixed";
		regulator-name = "eSMPS3_3P3";
		regulator-min-microvolt = <0x325aa0>;
		regulator-max-microvolt = <0x325aa0>;
		regulator-always-on;
		phandle = <0x27>;
	};

	__symbols__ {
		xo_board = "/clocks/xo-board";
		CPU0 = "/cpus/cpu@100";
		CPU1 = "/cpus/cpu@101";
		CPU2 = "/cpus/cpu@102";
		CPU3 = "/cpus/cpu@103";
		L2_0 = "/cpus/l2-cache";
		CPU_SLEEP_0 = "/cpus/idle-states/cpu-sleep-0";
		scm = "/firmware/scm";
		tz_apps_mem = "/reserved-memory/memory@85900000";
		xbl_mem = "/reserved-memory/memory@85e00000";
		smem_region = "/reserved-memory/memory@85f00000";
		tz_mem = "/reserved-memory/memory@86100000";
		wlan_fw_mem = "/reserved-memory/memory@86400000";
		adsp_fw_mem = "/reserved-memory/memory@87500000";
		cdsp_fw_mem = "/reserved-memory/memory@88f00000";
		wlan_msa_mem = "/reserved-memory/memory@89500000";
		uefi_mem = "/reserved-memory/memory@9f800000";
		rpm_requests = "/rpm-glink/glink-channel";
		rpmcc = "/rpm-glink/glink-channel/clock-controller";
		rpmpd = "/rpm-glink/glink-channel/power-controller";
		rpmpd_opp_table = "/rpm-glink/glink-channel/power-controller/opp-table";
		rpmpd_opp_ret = "/rpm-glink/glink-channel/power-controller/opp-table/opp1";
		rpmpd_opp_ret_plus = "/rpm-glink/glink-channel/power-controller/opp-table/opp2";
		rpmpd_opp_min_svs = "/rpm-glink/glink-channel/power-controller/opp-table/opp3";
		rpmpd_opp_low_svs = "/rpm-glink/glink-channel/power-controller/opp-table/opp4";
		rpmpd_opp_svs = "/rpm-glink/glink-channel/power-controller/opp-table/opp5";
		rpmpd_opp_svs_plus = "/rpm-glink/glink-channel/power-controller/opp-table/opp6";
		rpmpd_opp_nom = "/rpm-glink/glink-channel/power-controller/opp-table/opp7";
		rpmpd_opp_nom_plus = "/rpm-glink/glink-channel/power-controller/opp-table/opp8";
		rpmpd_opp_turbo = "/rpm-glink/glink-channel/power-controller/opp-table/opp9";
		rpmpd_opp_turbo_no_cpr = "/rpm-glink/glink-channel/power-controller/opp-table/opp10";
		rpmpd_opp_turbo_plus = "/rpm-glink/glink-channel/power-controller/opp-table/opp11";
		vreg_s4_1p8 = "/rpm-glink/glink-channel/pms405-regulators/s4";
		vreg_s5_1p35 = "/rpm-glink/glink-channel/pms405-regulators/s5";
		vreg_l1_1p3 = "/rpm-glink/glink-channel/pms405-regulators/l1";
		vreg_l2_1p275 = "/rpm-glink/glink-channel/pms405-regulators/l2";
		vreg_l3_1p05 = "/rpm-glink/glink-channel/pms405-regulators/l3";
		vreg_l4_1p2 = "/rpm-glink/glink-channel/pms405-regulators/l4";
		vreg_l5_1p8 = "/rpm-glink/glink-channel/pms405-regulators/l5";
		vreg_l6_1p8 = "/rpm-glink/glink-channel/pms405-regulators/l6";
		vreg_l7_1p8 = "/rpm-glink/glink-channel/pms405-regulators/l7";
		vreg_l8_1p2 = "/rpm-glink/glink-channel/pms405-regulators/l8";
		vreg_l10_3p3 = "/rpm-glink/glink-channel/pms405-regulators/l10";
		vreg_l11_sdc2 = "/rpm-glink/glink-channel/pms405-regulators/l11";
		vreg_l12_3p3 = "/rpm-glink/glink-channel/pms405-regulators/l12";
		vreg_l13_3p3 = "/rpm-glink/glink-channel/pms405-regulators/l13";
		tcsr_mutex = "/hwlock";
		soc = "/soc@0";
		turingcc = "/soc@0/clock-controller@800000";
		rpm_msg_ram = "/soc@0/memory@60000";
		qfprom = "/soc@0/qfprom@a4000";
		tsens_caldata = "/soc@0/qfprom@a4000/caldata@d0";
		rng = "/soc@0/rng@e3000";
		tsens = "/soc@0/thermal-sensor@4a9000";
		remoteproc_cdsp = "/soc@0/remoteproc@b00000";
		tlmm = "/soc@0/pinctrl@1000000";
		blsp1_i2c0_default = "/soc@0/pinctrl@1000000/blsp1-i2c0-default";
		blsp1_i2c1_default = "/soc@0/pinctrl@1000000/blsp1-i2c1-default";
		blsp1_i2c2_default = "/soc@0/pinctrl@1000000/blsp1-i2c2-default";
		blsp1_i2c3_default = "/soc@0/pinctrl@1000000/blsp1-i2c3-default";
		blsp1_i2c4_default = "/soc@0/pinctrl@1000000/blsp1-i2c4-default";
		blsp1_uart0_default = "/soc@0/pinctrl@1000000/blsp1-uart0-default";
		blsp1_uart1_default = "/soc@0/pinctrl@1000000/blsp1-uart1-default";
		blsp1_uart2_default = "/soc@0/pinctrl@1000000/blsp1-uart2-default";
		blsp1_uart3_default = "/soc@0/pinctrl@1000000/blsp1-uart3-default";
		blsp2_i2c0_default = "/soc@0/pinctrl@1000000/blsp2-i2c0-default";
		blsp1_spi0_default = "/soc@0/pinctrl@1000000/blsp1-spi0-default";
		blsp1_spi1_default = "/soc@0/pinctrl@1000000/blsp1-spi1-default";
		blsp1_spi2_default = "/soc@0/pinctrl@1000000/blsp1-spi2-default";
		blsp1_spi3_default = "/soc@0/pinctrl@1000000/blsp1-spi3-default";
		blsp1_spi4_default = "/soc@0/pinctrl@1000000/blsp1-spi4-default";
		blsp2_spi0_default = "/soc@0/pinctrl@1000000/blsp2-spi0-default";
		blsp2_uart0_default = "/soc@0/pinctrl@1000000/blsp2-uart0-default";
		perst_state = "/soc@0/pinctrl@1000000/perst";
		sdc1_on = "/soc@0/pinctrl@1000000/sdc1-on";
		sdc1_off = "/soc@0/pinctrl@1000000/sdc1-off";
		gcc = "/soc@0/clock-controller@1800000";
		tcsr_mutex_regs = "/soc@0/syscon@1905000";
		tcsr = "/soc@0/syscon@1937000";
		spmi_bus = "/soc@0/spmi@200f000";
		pms405_0 = "/soc@0/spmi@200f000/pms405@0";
		pms405_gpios = "/soc@0/spmi@200f000/pms405@0/gpio@c000";
		pms405_temp = "/soc@0/spmi@200f000/pms405@0/temp-alarm@2400";
		pms405_adc = "/soc@0/spmi@200f000/pms405@0/adc@3100";
		pon_1 = "/soc@0/spmi@200f000/pms405@0/adc@3100/vph_pwr@131";
		pa_therm1 = "/soc@0/spmi@200f000/pms405@0/adc@3100/thermistor1@77";
		pa_therm3 = "/soc@0/spmi@200f000/pms405@0/adc@3100/thermistor3@79";
		xo_therm = "/soc@0/spmi@200f000/pms405@0/adc@3100/xo_temp@76";
		pms405_1 = "/soc@0/spmi@200f000/pms405@1";
		pms405_spmi_regulators = "/soc@0/spmi@200f000/pms405@1/regulators";
		pms405_s3 = "/soc@0/spmi@200f000/pms405@1/regulators/s3";
		remoteproc_wcss = "/soc@0/remoteproc@7400000";
		pcie_phy = "/soc@0/phy@7786000";
		sdcc1 = "/soc@0/sdcc@7804000";
		blsp1_dma = "/soc@0/dma@7884000";
		blsp1_uart0 = "/soc@0/serial@78af000";
		blsp1_uart1 = "/soc@0/serial@78b0000";
		blsp1_uart2 = "/soc@0/serial@78b1000";
		ethernet = "/soc@0/ethernet@7a80000";
		wifi = "/soc@0/wifi@a000000";
		blsp1_uart3 = "/soc@0/serial@78b2000";
		blsp1_i2c0 = "/soc@0/i2c@78b5000";
		blsp1_spi0 = "/soc@0/spi@78b5000";
		blsp1_i2c1 = "/soc@0/i2c@78b6000";
		blsp1_spi1 = "/soc@0/spi@78b6000";
		blsp1_i2c2 = "/soc@0/i2c@78b7000";
		blsp1_spi2 = "/soc@0/spi@78b7000";
		blsp1_i2c3 = "/soc@0/i2c@78b8000";
		blsp1_spi3 = "/soc@0/spi@78b8000";
		blsp1_i2c4 = "/soc@0/i2c@78b9000";
		blsp1_spi4 = "/soc@0/spi@78b9000";
		blsp2_dma = "/soc@0/dma@7ac4000";
		blsp2_uart0 = "/soc@0/serial@7aef000";
		blsp2_i2c0 = "/soc@0/i2c@7af5000";
		blsp2_spi0 = "/soc@0/spi@7af5000";
		intc = "/soc@0/interrupt-controller@b000000";
		apcs_glb = "/soc@0/mailbox@b011000";
		remoteproc_adsp = "/soc@0/remoteproc@c700000";
		pcie = "/soc@0/pci@10000000";
		adsp_smp2p_out = "/smp2p-adsp/master-kernel";
		adsp_smp2p_in = "/smp2p-adsp/slave-kernel";
		cdsp_smp2p_out = "/smp2p-cdsp/master-kernel";
		cdsp_smp2p_in = "/smp2p-cdsp/slave-kernel";
		wcss_smp2p_out = "/smp2p-wcss/master-kernel";
		wcss_smp2p_in = "/smp2p-wcss/slave-kernel";
		aoss_alert0 = "/thermal-zones/aoss-thermal/trips/trip-point0";
		q6_hvx_alert0 = "/thermal-zones/q6-hvx-thermal/trips/trip-point0";
		lpass_alert0 = "/thermal-zones/lpass-thermal/trips/trip-point0";
		wlan_alert0 = "/thermal-zones/wlan-thermal/trips/trip-point0";
		cluster_alert0 = "/thermal-zones/cluster-thermal/trips/trip-point0";
		cluster_alert1 = "/thermal-zones/cluster-thermal/trips/trip-point1";
		cluster_crit = "/thermal-zones/cluster-thermal/trips/cluster_crit";
		cpu0_alert0 = "/thermal-zones/cpu0-thermal/trips/trip-point0";
		cpu0_alert1 = "/thermal-zones/cpu0-thermal/trips/trip-point1";
		cpu0_crit = "/thermal-zones/cpu0-thermal/trips/cpu_crit";
		cpu1_alert0 = "/thermal-zones/cpu1-thermal/trips/trip-point0";
		cpu1_alert1 = "/thermal-zones/cpu1-thermal/trips/trip-point1";
		cpu1_crit = "/thermal-zones/cpu1-thermal/trips/cpu_crit";
		cpu2_alert0 = "/thermal-zones/cpu2-thermal/trips/trip-point0";
		cpu2_alert1 = "/thermal-zones/cpu2-thermal/trips/trip-point1";
		cpu2_crit = "/thermal-zones/cpu2-thermal/trips/cpu_crit";
		cpu3_alert0 = "/thermal-zones/cpu3-thermal/trips/trip-point0";
		cpu3_alert1 = "/thermal-zones/cpu3-thermal/trips/trip-point1";
		cpu3_crit = "/thermal-zones/cpu3-thermal/trips/cpu_crit";
		gpu_alert0 = "/thermal-zones/gpu-thermal/trips/trip-point0";
		pms405_alert0 = "/thermal-zones/pms405/trips/pms405-alert0";
		pms405_crit = "/thermal-zones/pms405/trips/pms405-crit";
		vph_pwr = "/vph-pwr-regulator";
		vdd_ch0_3p3 = "/vdd-esmps3-3p3-regulator";
		vdd_esmps3_3p3 = "/vdd-esmps3-3p3-regulator";
	};
};
